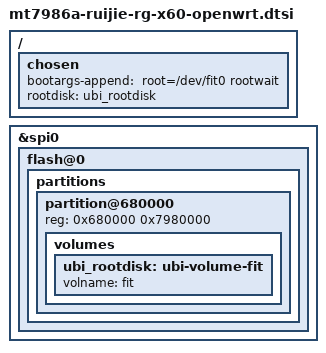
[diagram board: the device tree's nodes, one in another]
// SPDX-License-Identifier: GPL-2.0-or-later OR MIT

/ {
	chosen {
		bootargs-append = " root=/dev/fit0 rootwait";
		rootdisk = <&ubi_rootdisk>;
	};
};

&spi0 {
	flash@0 {
		/delete-property/ mediatek,nmbm;
		/delete-property/ mediatek,bmt-max-ratio;
		/delete-property/ mediatek,bmt-max-reserved-blocks;

		partitions {
			partition@680000 {
				reg = <0x680000 0x7980000>;

				volumes {
					ubi_rootdisk: ubi-volume-fit {
						volname = "fit";
					};
				};
			};
		};
	};
};
